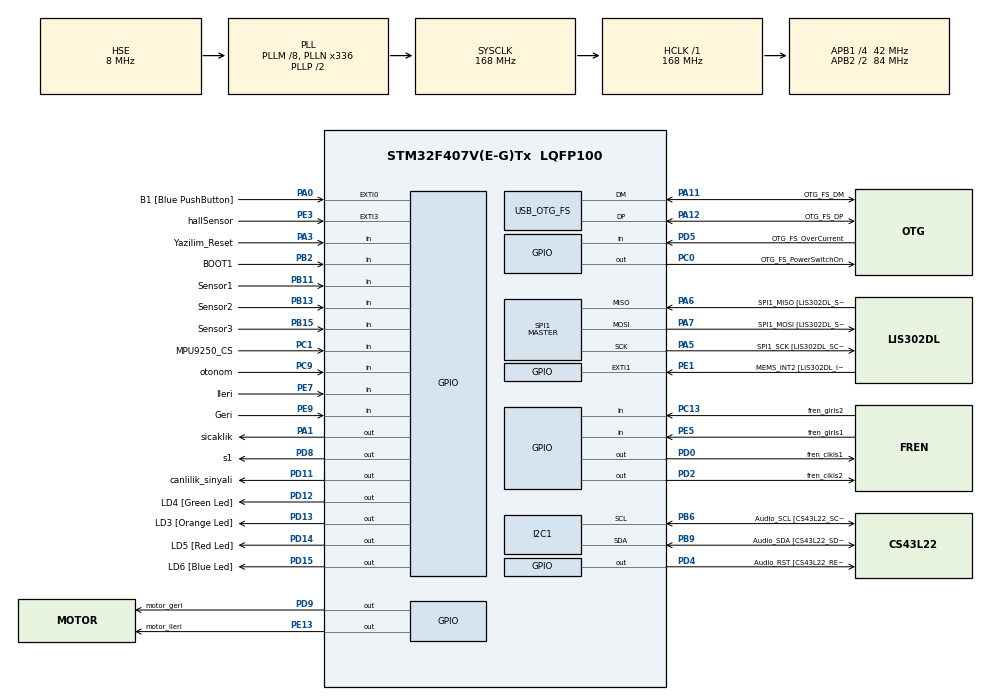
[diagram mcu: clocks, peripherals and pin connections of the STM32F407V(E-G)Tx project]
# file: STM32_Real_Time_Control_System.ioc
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FREERTOS.Tasks01=ControlTask,48,512,StartControlTask,Default,NULL,Dynamic,NULL,NULL;NavigationTask,8,1024,StartNavigationTask,Default,NULL,Dynamic,NULL,NULL;IMUTask,8,512,StartIMUTask,Default,NULL,Dynamic,NULL,NULL;SensorTask,8,512,StartSensorTask,Default,NULL,Dynamic,NULL,NULL;TelemetryTask,8,1024,StartTelemetryTask,Default,NULL,Dynamic,NULL,NULL;ReflectorTask,40,512,StartReflectorTask,Default,NULL,Dynamic,NULL,NULL
FREERTOS.configUSE_NEWLIB_REENTRANT=1
Mcu.Family=STM32F4
Mcu.Name=STM32F407V(E-G)Tx
Mcu.Package=LQFP100
NVIC.OTG_FS_IRQn=true\:5\:0\:false\:false\:true\:true\:true\:true\:true
NVIC.PriorityGroup=NVIC_PRIORITYGROUP_4
NVIC.TIM6_DAC_IRQn=true\:15\:0\:false\:false\:true\:false\:false\:true\:true
NVIC.TimeBase=TIM6_DAC_IRQn
NVIC.TimeBaseIP=TIM6
PA0-WKUP.GPIO_Label=B1 [Blue PushButton]
PA0-WKUP.GPIO_ModeDefaultEXTI=GPIO_MODE_EVT_RISING
PA0-WKUP.GPIO_PuPd=GPIO_NOPULL
PA0-WKUP.Signal=GPXTI0
PA1.GPIO_Label=sicaklik
PA1.GPIO_ModeDefaultOutputPP=GPIO_MODE_OUTPUT_OD
PA1.GPIO_PuPd=GPIO_PULLUP
PA1.GPIO_Speed=GPIO_SPEED_FREQ_HIGH
PA1.Signal=GPIO_Output
PA10.GPIO_Label=OTG_FS_ID
PA10.GPIO_Mode=GPIO_MODE_AF_PP
PA10.GPIO_PuPd=GPIO_NOPULL
PA10.GPIO_Speed=GPIO_SPEED_FREQ_LOW
PA10.Signal=USB_OTG_FS_ID
PA11.GPIO_Label=OTG_FS_DM
PA11.GPIO_Mode=GPIO_MODE_AF_PP
PA11.GPIO_PuPd=GPIO_NOPULL
PA11.GPIO_Speed=GPIO_SPEED_FREQ_LOW
PA11.Mode=Device_Only
PA11.Signal=USB_OTG_FS_DM
PA12.GPIO_Label=OTG_FS_DP
PA12.GPIO_Mode=GPIO_MODE_AF_PP
PA12.GPIO_PuPd=GPIO_NOPULL
PA12.GPIO_Speed=GPIO_SPEED_FREQ_LOW
PA12.Mode=Device_Only
PA12.Signal=USB_OTG_FS_DP
PA13.GPIO_Label=SWDIO
PA13.Mode=Serial_Wire
PA13.Signal=SYS_JTMS-SWDIO
PA14.GPIO_Label=SWCLK
PA14.Mode=Serial_Wire
PA14.Signal=SYS_JTCK-SWCLK
PA3.GPIO_Label=Yazilim_Reset
PA3.GPIO_PuPd=GPIO_PULLDOWN
PA3.Signal=GPIO_Input
PA4.GPIO_Label=I2S3_WS [CS43L22_LRCK]
PA4.GPIO_Mode=GPIO_MODE_AF_PP
PA4.GPIO_PuPd=GPIO_NOPULL
PA4.GPIO_Speed=GPIO_SPEED_FREQ_LOW
PA4.Signal=I2S3_WS
PA5.GPIO_Label=SPI1_SCK [LIS302DL_SCL/SPC]
PA5.GPIO_Mode=GPIO_MODE_AF_PP
PA5.GPIO_PuPd=GPIO_NOPULL
PA5.GPIO_Speed=GPIO_SPEED_FREQ_LOW
PA5.Mode=Full_Duplex_Master
PA5.Signal=SPI1_SCK
PA6.GPIO_Label=SPI1_MISO [LIS302DL_SDO]
PA6.GPIO_Mode=GPIO_MODE_AF_PP
PA6.GPIO_PuPd=GPIO_NOPULL
PA6.GPIO_Speed=GPIO_SPEED_FREQ_LOW
PA6.Mode=Full_Duplex_Master
PA6.Signal=SPI1_MISO
PA7.GPIO_Label=SPI1_MOSI [LIS302DL_SDA/SDI/SDO]
PA7.GPIO_Mode=GPIO_MODE_AF_PP
PA7.GPIO_PuPd=GPIO_NOPULL
PA7.GPIO_Speed=GPIO_SPEED_FREQ_LOW
PA7.Mode=Full_Duplex_Master
PA7.Signal=SPI1_MOSI
PA9.GPIO_Label=VBUS_FS
PA9.GPIO_Mode=GPIO_MODE_INPUT
PA9.GPIO_PuPd=GPIO_NOPULL
PA9.Signal=USB_OTG_FS_VBUS
PB10.GPIO_Label=CLK_IN [MP45DT02_CLK]
PB10.GPIO_Mode=GPIO_MODE_AF_PP
PB10.GPIO_PuPd=GPIO_NOPULL
PB10.GPIO_Speed=GPIO_SPEED_FREQ_LOW
PB10.Signal=I2S2_CK
PB11.GPIO_Label=Sensor1
PB11.GPIO_PuPd=GPIO_NOPULL
PB11.Signal=GPIO_Input
PB13.GPIO_Label=Sensor2
PB13.GPIO_PuPd=GPIO_NOPULL
PB13.Signal=GPIO_Input
PB15.GPIO_Label=Sensor3
PB15.GPIO_PuPd=GPIO_NOPULL
PB15.Signal=GPIO_Input
PB2.GPIO_Label=BOOT1
PB2.GPIO_Mode=GPIO_MODE_INPUT
PB2.GPIO_PuPd=GPIO_NOPULL
PB2.Signal=GPIO_Input
PB3.GPIO_Label=SWO
PB3.Signal=SYS_JTDO-SWO
PB6.GPIO_Label=Audio_SCL [CS43L22_SCL]
PB6.GPIO_Mode=GPIO_MODE_AF_OD
PB6.GPIO_Pu=GPIO_PULLUP
PB6.GPIO_PuPd=GPIO_NOPULL
PB6.GPIO_Speed=GPIO_SPEED_FREQ_HIGH
PB6.Mode=I2C
PB6.Signal=I2C1_SCL
PB9.GPIO_Label=Audio_SDA [CS43L22_SDA]
PB9.GPIO_Mode=GPIO_MODE_AF_OD
PB9.GPIO_Pu=GPIO_PULLUP
PB9.GPIO_PuPd=GPIO_NOPULL
PB9.GPIO_Speed=GPIO_SPEED_FREQ_HIGH
PB9.Mode=I2C
PB9.Signal=I2C1_SDA
PC0.GPIO_Label=OTG_FS_PowerSwitchOn
PC0.GPIO_PuPd=GPIO_NOPULL
PC0.GPIO_Speed=GPIO_SPEED_FREQ_LOW
PC0.PinState=GPIO_PIN_SET
PC0.Signal=GPIO_Output
PC1.GPIO_Label=MPU9250_CS
PC1.Signal=GPIO_Input
PC10.GPIO_Label=I2S3_SCK [CS43L22_SCLK]
PC10.GPIO_Mode=GPIO_MODE_AF_PP
PC10.GPIO_PuPd=GPIO_NOPULL
PC10.GPIO_Speed=GPIO_SPEED_FREQ_LOW
PC10.Signal=I2S3_CK
PC13-ANTI_TAMP.GPIO_Label=fren_giris2
PC13-ANTI_TAMP.GPIO_PuPd=GPIO_PULLDOWN
PC13-ANTI_TAMP.Signal=GPIO_Input
PC14-OSC32_IN.GPIO_Label=PC14-OSC32_IN
PC14-OSC32_IN.Mode=LSE-External-Oscillator
PC14-OSC32_IN.Signal=RCC_OSC32_IN
PC15-OSC32_OUT.GPIO_Label=PC15-OSC32_OUT
PC15-OSC32_OUT.Mode=LSE-External-Oscillator
PC15-OSC32_OUT.Signal=RCC_OSC32_OUT
PC3.GPIO_Label=PDM_OUT [MP45DT02_DOUT]
PC3.GPIO_Mode=GPIO_MODE_AF_PP
PC3.GPIO_PuPd=GPIO_NOPULL
PC3.GPIO_Speed=GPIO_SPEED_FREQ_LOW
PC3.Signal=I2S2_SD
PC7.GPIO_Label=I2S3_MCK [CS43L22_MCLK]
PC7.GPIO_Mode=GPIO_MODE_AF_PP
PC7.GPIO_PuPd=GPIO_NOPULL
PC7.GPIO_Speed=GPIO_SPEED_FREQ_LOW
PC7.Signal=I2S3_MCK
PC9.GPIO_Label=otonom
PC9.GPIO_PuPd=GPIO_PULLDOWN
PC9.Signal=GPIO_Input
PD0.GPIO_Label=fren_cikis1
PD0.PinState=GPIO_PIN_SET
PD0.Signal=GPIO_Output
PD11.GPIO_Label=canlilik_sinyali
PD11.Signal=GPIO_Output
PD12.GPIO_Label=LD4 [Green Led]
PD12.GPIO_PuPd=GPIO_NOPULL
PD12.GPIO_Speed=GPIO_SPEED_FREQ_LOW
PD12.Signal=GPIO_Output
PD13.GPIO_Label=LD3 [Orange Led]
PD13.GPIO_PuPd=GPIO_NOPULL
PD13.GPIO_Speed=GPIO_SPEED_FREQ_LOW
PD13.Signal=GPIO_Output
PD14.GPIO_Label=LD5 [Red Led]
PD14.GPIO_PuPd=GPIO_NOPULL
PD14.GPIO_Speed=GPIO_SPEED_FREQ_LOW
PD14.Signal=GPIO_Output
PD15.GPIO_Label=LD6 [Blue Led]
PD15.GPIO_PuPd=GPIO_NOPULL
PD15.GPIO_Speed=GPIO_SPEED_FREQ_LOW
PD15.Signal=GPIO_Output
PD2.GPIO_Label=fren_cikis2
PD2.GPIO_ModeDefaultOutputPP=GPIO_MODE_OUTPUT_OD
PD2.GPIO_PuPd=GPIO_PULLUP
PD2.PinState=GPIO_PIN_SET
PD2.Signal=GPIO_Output
PD4.GPIO_Label=Audio_RST [CS43L22_RESET]
PD4.GPIO_PuPd=GPIO_NOPULL
PD4.GPIO_Speed=GPIO_SPEED_FREQ_LOW
PD4.Signal=GPIO_Output
PD5.GPIO_Label=OTG_FS_OverCurrent
PD5.GPIO_Mode=GPIO_MODE_INPUT
PD5.GPIO_PuPd=GPIO_NOPULL
PD5.Signal=GPIO_Input
PD8.GPIO_Label=s1
PD8.Signal=GPIO_Output
PD9.GPIO_Label=motor_geri
PD9.PinState=GPIO_PIN_SET
PD9.Signal=GPIO_Output
PE1.GPIO_Label=MEMS_INT2 [LIS302DL_INT2]
PE1.GPIO_ModeDefaultEXTI=GPIO_MODE_EVT_RISING
PE1.GPIO_PuPd=GPIO_NOPULL
PE1.Signal=GPXTI1
PE13.GPIO_Label=motor_ileri
PE13.PinState=GPIO_PIN_SET
PE13.Signal=GPIO_Output
PE3.GPIO_Label=hallSensor
PE3.GPIO_ModeDefaultEXTI=GPIO_MODE_IT_FALLING
PE3.GPIO_PuPd=GPIO_PULLDOWN
PE3.Signal=GPXTI3
PE5.GPIO_Label=fren_giris1
PE5.GPIO_PuPd=GPIO_PULLDOWN
PE5.Signal=GPIO_Input
PE7.GPIO_Label=Ileri
PE7.GPIO_PuPd=GPIO_PULLDOWN
PE7.Signal=GPIO_Input
PE9.GPIO_Label=Geri
PE9.GPIO_PuPd=GPIO_PULLDOWN
PE9.Signal=GPIO_Input
PH0-OSC_IN.GPIO_Label=PH0-OSC_IN
PH0-OSC_IN.Mode=HSE-External-Oscillator
PH0-OSC_IN.Signal=RCC_OSC_IN
PH1-OSC_OUT.GPIO_Label=PH1-OSC_OUT
PH1-OSC_OUT.Mode=HSE-External-Oscillator
PH1-OSC_OUT.Signal=RCC_OSC_OUT
ProjectManager.HeapSize=0x200
ProjectManager.StackSize=0x400
ProjectManager.TargetToolchain=STM32CubeIDE
RCC.48MHZClocksFreq_Value=48000000
RCC.AHBFreq_Value=168000000
RCC.APB1CLKDivider=RCC_HCLK_DIV4
RCC.APB1Freq_Value=42000000
RCC.APB1TimFreq_Value=84000000
RCC.APB2CLKDivider=RCC_HCLK_DIV2
RCC.APB2Freq_Value=84000000
RCC.APB2TimFreq_Value=168000000
RCC.CortexFreq_Value=168000000
RCC.HCLKFreq_Value=168000000
RCC.HSE_VALUE=8000000
RCC.HSI_VALUE=16000000
RCC.PLLM=8
RCC.PLLN=336
RCC.PLLQ=7
RCC.SYSCLKFreq_VALUE=168000000
RCC.SYSCLKSource=RCC_SYSCLKSOURCE_PLLCLK
RCC.VCOOutputFreq_Value=336000000
SPI1.BaudRatePrescaler-Full_Duplex_Master=SPI_BAUDRATEPRESCALER_2
SPI1.CalculateBaudRate-Full_Duplex_Master=42.0 MBits/s
SPI1.Direction=SPI_DIRECTION_2LINES
SPI1.Mode=SPI_MODE_MASTER
SPI1.Mode-Full_Duplex_Master=SPI_MODE_MASTER
SPI1.VirtualType=VM_MASTER
TIM2.Prescaler=83
USB_DEVICE.CLASS_NAME_FS=CDC
USB_DEVICE.VirtualMode-CDC_FS=Cdc
USB_DEVICE.VirtualModeFS=Cdc_FS
USB_OTG_FS.VirtualMode=Device_Only
VP_FREERTOS_VS_CMSIS_V2.Mode=CMSIS_V2
VP_SYS_VS_tim6.Mode=TIM6
VP_TIM2_VS_ClockSourceINT.Mode=Internal
VP_USB_DEVICE_VS_USB_DEVICE_CDC_FS.Mode=CDC_FS
board=STM32F407G-DISC1

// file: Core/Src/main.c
/* USER CODE BEGIN Header */
/**
  ******************************************************************************
  * @file           : main.c
  * @brief          : Main program body
  ******************************************************************************
  * @attention
  *
  * Copyright (c) 2026 STMicroelectronics.
  * All rights reserved.
  *
  * This software is licensed under terms that can be found in the LICENSE file
  * in the root directory of this software component.
  * If no LICENSE file comes with this software, it is provided AS-IS.
  *
  ******************************************************************************
  */
/* USER CODE END Header */
#include "main.h"
#include "cmsis_os.h"
#include "usb_device.h"

I2C_HandleTypeDef hi2c1;

SPI_HandleTypeDef hspi1;

TIM_HandleTypeDef htim2;

/* Definitions for ControlTask */
osThreadId_t ControlTaskHandle;
const osThreadAttr_t ControlTask_attributes = {
  .name = "ControlTask",
  .stack_size = 512 * 4,
  .priority = (osPriority_t) osPriorityRealtime,
};
/* Definitions for NavigationTask */
osThreadId_t NavigationTaskHandle;
const osThreadAttr_t NavigationTask_attributes = {
  .name = "NavigationTask",
  .stack_size = 1024 * 4,
  .priority = (osPriority_t) osPriorityLow,
};
/* Definitions for IMUTask */
osThreadId_t IMUTaskHandle;
const osThreadAttr_t IMUTask_attributes = {
  .name = "IMUTask",
  .stack_size = 512 * 4,
  .priority = (osPriority_t) osPriorityLow,
};
/* Definitions for SensorTask */
osThreadId_t SensorTaskHandle;
const osThreadAttr_t SensorTask_attributes = {
  .name = "SensorTask",
  .stack_size = 512 * 4,
  .priority = (osPriority_t) osPriorityLow,
};
/* Definitions for TelemetryTask */
osThreadId_t TelemetryTaskHandle;
const osThreadAttr_t TelemetryTask_attributes = {
  .name = "TelemetryTask",
  .stack_size = 1024 * 4,
  .priority = (osPriority_t) osPriorityLow,
};

void SystemClock_Config(void);
static void MX_GPIO_Init(void);
static void MX_I2C1_Init(void);
static void MX_SPI1_Init(void);
static void MX_TIM2_Init(void);
void StartControlTask(void *argument);
void StartNavigationTask(void *argument);
void StartIMUTask(void *argument);
void StartSensorTask(void *argument);
void StartTelemetryTask(void *argument);

/* USER CODE BEGIN 0 */
void I2C_Hatti_Kurtar(void)
{
    GPIO_InitTypeDef GPIO_InitStruct = {0};
    __HAL_RCC_GPIOB_CLK_ENABLE();

    // SCL (PB6) ve SDA (PB9) pinlerini standart çıkış olarak ayarla
    GPIO_InitStruct.Pin = GPIO_PIN_6 | GPIO_PIN_9;
    GPIO_InitStruct.Mode = GPIO_MODE_OUTPUT_OD; // Open Drain
    GPIO_InitStruct.Pull = GPIO_PULLUP;
    GPIO_InitStruct.Speed = GPIO_SPEED_FREQ_HIGH;
    HAL_GPIO_Init(GPIOB, &GPIO_InitStruct);

    // SDA'yı serbest bırak ve SCL'ye 9 kez manuel saat palsi gönder (Sensörü hattan düşür)
    HAL_GPIO_WritePin(GPIOB, GPIO_PIN_9, GPIO_PIN_SET);

    for(int i = 0; i < 9; i++)
    {
        HAL_GPIO_WritePin(GPIOB, GPIO_PIN_6, GPIO_PIN_RESET); // SCL Low
        HAL_Delay(1);
        HAL_GPIO_WritePin(GPIOB, GPIO_PIN_6, GPIO_PIN_SET);   // SCL High
        HAL_Delay(1);
    }

    // STOP durumu oluştur
    HAL_GPIO_WritePin(GPIOB, GPIO_PIN_6, GPIO_PIN_RESET);
    HAL_Delay(1);
    HAL_GPIO_WritePin(GPIOB, GPIO_PIN_9, GPIO_PIN_RESET);
    HAL_Delay(1);
    HAL_GPIO_WritePin(GPIOB, GPIO_PIN_6, GPIO_PIN_SET);
    HAL_Delay(1);
    HAL_GPIO_WritePin(GPIOB, GPIO_PIN_9, GPIO_PIN_SET);
    HAL_Delay(1);
}
/* USER CODE END 0 */

int main(void)
{

  /* MCU Configuration--------------------------------------------------------*/

  /* Reset of all peripherals, Initializes the Flash interface and the Systick. */
  HAL_Init();

  /* Configure the system clock */
  SystemClock_Config();

  /* Initialize all configured peripherals */
  MX_GPIO_Init();

  /*
   * Bataryadan ilk enerji verildiginde BNO055'in dahili regilatorunun,
   * islemcisinin ve I2C cikislarinin tamamen hazir olmasini bekle.
   * USB ile beslemede olusan dogal gecikme bataryada bulunmadigi icin
   * bu bekleme soguk acilis sorununu engeller.
   */
  HAL_Delay(1500);

  /* BNO055 acilista I2C hattini kilitlediyse 9 SCL palsi ve STOP ile kurtar. */
  I2C_Hatti_Kurtar();

  /* GPIO modundan I2C alternatif fonksiyonuna gecmeden once hatti serbest birak. */
  HAL_Delay(10);

  MX_I2C1_Init();
  MX_SPI1_Init();
  MX_TIM2_Init();
  MX_USB_DEVICE_Init();
  /* USER CODE BEGIN 2 */
  HAL_TIM_Base_Start(&htim2);
  /* USER CODE END 2 */

  /* Init scheduler */
  osKernelInitialize();

  /* Create the thread(s) */
  /* creation of ControlTask */
  ControlTaskHandle = osThreadNew(StartControlTask, NULL, &ControlTask_attributes);

  /* creation of NavigationTask */
  NavigationTaskHandle = osThreadNew(StartNavigationTask, NULL, &NavigationTask_attributes);

  /* creation of IMUTask */
  IMUTaskHandle = osThreadNew(StartIMUTask, NULL, &IMUTask_attributes);

  /* creation of SensorTask */
  SensorTaskHandle = osThreadNew(StartSensorTask, NULL, &SensorTask_attributes);

  /* creation of TelemetryTask */
  TelemetryTaskHandle = osThreadNew(StartTelemetryTask, NULL, &TelemetryTask_attributes);

  /* Start scheduler */
  osKernelStart();

  /* We should never get here as control is now taken by the scheduler */

  /* Infinite loop */
  while (1)
  {

  }
}

void SystemClock_Config(void)
{
  RCC_OscInitTypeDef RCC_OscInitStruct = {0};
  RCC_ClkInitTypeDef RCC_ClkInitStruct = {0};

  /** Configure the main internal regulator output voltage
  */
  __HAL_RCC_PWR_CLK_ENABLE();
  __HAL_PWR_VOLTAGESCALING_CONFIG(PWR_REGULATOR_VOLTAGE_SCALE1);

  /** Initializes the RCC Oscillators according to the specified parameters in the RCC_OscInitTypeDef structure.
  */
  RCC_OscInitStruct.OscillatorType = RCC_OSCILLATORTYPE_HSE;
  RCC_OscInitStruct.HSEState = RCC_HSE_ON;
  RCC_OscInitStruct.PLL.PLLState = RCC_PLL_ON;
  RCC_OscInitStruct.PLL.PLLSource = RCC_PLLSOURCE_HSE;
  RCC_OscInitStruct.PLL.PLLM = 8;
  RCC_OscInitStruct.PLL.PLLN = 336;
  RCC_OscInitStruct.PLL.PLLP = RCC_PLLP_DIV2;
  RCC_OscInitStruct.PLL.PLLQ = 7;
  if (HAL_RCC_OscConfig(&RCC_OscInitStruct) != HAL_OK)
  {
    Error_Handler();
  }

  /** Initializes the CPU, AHB and APB buses clocks
  */
  RCC_ClkInitStruct.ClockType = RCC_CLOCKTYPE_HCLK|RCC_CLOCKTYPE_SYSCLK
                              |RCC_CLOCKTYPE_PCLK1|RCC_CLOCKTYPE_PCLK2;
  RCC_ClkInitStruct.SYSCLKSource = RCC_SYSCLKSOURCE_PLLCLK;
  RCC_ClkInitStruct.AHBCLKDivider = RCC_SYSCLK_DIV1;
  RCC_ClkInitStruct.APB1CLKDivider = RCC_HCLK_DIV4;
  RCC_ClkInitStruct.APB2CLKDivider = RCC_HCLK_DIV2;

  if (HAL_RCC_ClockConfig(&RCC_ClkInitStruct, FLASH_LATENCY_5) != HAL_OK)
  {
    Error_Handler();
  }
}

static void MX_I2C1_Init(void)
{

  hi2c1.Instance = I2C1;
  hi2c1.Init.ClockSpeed = 100000;
  hi2c1.Init.DutyCycle = I2C_DUTYCYCLE_2;
  hi2c1.Init.OwnAddress1 = 0;
  hi2c1.Init.AddressingMode = I2C_ADDRESSINGMODE_7BIT;
  hi2c1.Init.DualAddressMode = I2C_DUALADDRESS_DISABLE;
  hi2c1.Init.OwnAddress2 = 0;
  hi2c1.Init.GeneralCallMode = I2C_GENERALCALL_DISABLE;
  hi2c1.Init.NoStretchMode = I2C_NOSTRETCH_DISABLE;
  if (HAL_I2C_Init(&hi2c1) != HAL_OK)
  {
    Error_Handler();
  }

}

static void MX_SPI1_Init(void)
{

  /* SPI1 parameter configuration*/
  hspi1.Instance = SPI1;
  hspi1.Init.Mode = SPI_MODE_MASTER;
  hspi1.Init.Direction = SPI_DIRECTION_2LINES;
  hspi1.Init.DataSize = SPI_DATASIZE_8BIT;
  hspi1.Init.CLKPolarity = SPI_POLARITY_LOW;
  hspi1.Init.CLKPhase = SPI_PHASE_1EDGE;
  hspi1.Init.NSS = SPI_NSS_SOFT;
  hspi1.Init.BaudRatePrescaler = SPI_BAUDRATEPRESCALER_2;
  hspi1.Init.FirstBit = SPI_FIRSTBIT_MSB;
  hspi1.Init.TIMode = SPI_TIMODE_DISABLE;
  hspi1.Init.CRCCalculation = SPI_CRCCALCULATION_DISABLE;
  hspi1.Init.CRCPolynomial = 10;
  if (HAL_SPI_Init(&hspi1) != HAL_OK)
  {
    Error_Handler();
  }
  /* USER CODE BEGIN SPI1_Init 2 */
  HAL_NVIC_EnableIRQ(EXTI3_IRQn);
  /* USER CODE END SPI1_Init 2 */

}

static void MX_TIM2_Init(void)
{

  TIM_ClockConfigTypeDef sClockSourceConfig = {0};
  TIM_MasterConfigTypeDef sMasterConfig = {0};

  htim2.Instance = TIM2;
  htim2.Init.Prescaler = 83;
  htim2.Init.CounterMode = TIM_COUNTERMODE_UP;
  htim2.Init.Period = 4294967295;
  htim2.Init.ClockDivision = TIM_CLOCKDIVISION_DIV1;
  htim2.Init.AutoReloadPreload = TIM_AUTORELOAD_PRELOAD_DISABLE;
  if (HAL_TIM_Base_Init(&htim2) != HAL_OK)
  {
    Error_Handler();
  }
  sClockSourceConfig.ClockSource = TIM_CLOCKSOURCE_INTERNAL;
  if (HAL_TIM_ConfigClockSource(&htim2, &sClockSourceConfig) != HAL_OK)
  {
    Error_Handler();
  }
  sMasterConfig.MasterOutputTrigger = TIM_TRGO_RESET;
  sMasterConfig.MasterSlaveMode = TIM_MASTERSLAVEMODE_DISABLE;
  if (HAL_TIMEx_MasterConfigSynchronization(&htim2, &sMasterConfig) != HAL_OK)
  {
    Error_Handler();
  }

}

static void MX_GPIO_Init(void)
{
  GPIO_InitTypeDef GPIO_InitStruct = {0};

  /* GPIO Ports Clock Enable */
  __HAL_RCC_GPIOE_CLK_ENABLE();
  __HAL_RCC_GPIOC_CLK_ENABLE();
  __HAL_RCC_GPIOH_CLK_ENABLE();
  __HAL_RCC_GPIOA_CLK_ENABLE();
  __HAL_RCC_GPIOB_CLK_ENABLE();
  __HAL_RCC_GPIOD_CLK_ENABLE();

  /*Configure GPIO pin Output Level */
  HAL_GPIO_WritePin(OTG_FS_PowerSwitchOn_GPIO_Port, OTG_FS_PowerSwitchOn_Pin, GPIO_PIN_SET);

  /*Configure GPIO pin Output Level */
  HAL_GPIO_WritePin(sicaklik_GPIO_Port, sicaklik_Pin, GPIO_PIN_RESET);

  /*Configure GPIO pin Output Level */
  HAL_GPIO_WritePin(GPIOE, motor_ileri_Pin|fren_cikis1_Pin, GPIO_PIN_SET);

  /*Configure GPIO pin Output Level */
  HAL_GPIO_WritePin(GPIOD, s1_Pin|canlilik_sinyali_Pin|LD4_Pin|LD3_Pin
                          |LD5_Pin|LD6_Pin|Audio_RST_Pin, GPIO_PIN_RESET);

  /*Configure GPIO pin Output Level */
  HAL_GPIO_WritePin(GPIOD, motor_geri_Pin|fren_cikis2_Pin, GPIO_PIN_SET);

  /* I2C modunda GY-91 MPU NCS pini HIGH tutulur. */
  HAL_GPIO_WritePin(MPU9250_CS_GPIO_Port, MPU9250_CS_Pin, GPIO_PIN_SET);

  /*Configure GPIO pin : hallSensor_Pin */
  GPIO_InitStruct.Pin = hallSensor_Pin;
  GPIO_InitStruct.Mode = GPIO_MODE_IT_RISING_FALLING;
  GPIO_InitStruct.Pull = GPIO_NOPULL;
  HAL_GPIO_Init(hallSensor_GPIO_Port, &GPIO_InitStruct);

  /*Configure GPIO pins : fren_giris1_Pin Ileri_Pin Geri_Pin */
  GPIO_InitStruct.Pin = fren_giris1_Pin|Ileri_Pin|Geri_Pin;
  GPIO_InitStruct.Mode = GPIO_MODE_INPUT;
  GPIO_InitStruct.Pull = GPIO_PULLDOWN;
  HAL_GPIO_Init(GPIOE, &GPIO_InitStruct);

  /*Configure GPIO pins : fren_giris2_Pin otonom_Pin */
  GPIO_InitStruct.Pin = fren_giris2_Pin|otonom_Pin;
  GPIO_InitStruct.Mode = GPIO_MODE_INPUT;
  GPIO_InitStruct.Pull = GPIO_PULLDOWN;
  HAL_GPIO_Init(GPIOC, &GPIO_InitStruct);

  /*Configure GPIO pin : OTG_FS_PowerSwitchOn_Pin */
  GPIO_InitStruct.Pin = OTG_FS_PowerSwitchOn_Pin;
  GPIO_InitStruct.Mode = GPIO_MODE_OUTPUT_PP;
  GPIO_InitStruct.Pull = GPIO_NOPULL;
  GPIO_InitStruct.Speed = GPIO_SPEED_FREQ_LOW;
  HAL_GPIO_Init(OTG_FS_PowerSwitchOn_GPIO_Port, &GPIO_InitStruct);

  /*Configure GPIO pin : MPU9250_CS_Pin */
  GPIO_InitStruct.Pin = MPU9250_CS_Pin;
  GPIO_InitStruct.Mode = GPIO_MODE_OUTPUT_PP;
  GPIO_InitStruct.Pull = GPIO_NOPULL;
  GPIO_InitStruct.Speed = GPIO_SPEED_FREQ_LOW;
  HAL_GPIO_Init(MPU9250_CS_GPIO_Port, &GPIO_InitStruct);

  HAL_GPIO_WritePin(MPU9250_CS_GPIO_Port, MPU9250_CS_Pin, GPIO_PIN_SET);

  /*Configure GPIO pin : PDM_OUT_Pin */
  GPIO_InitStruct.Pin = PDM_OUT_Pin;
  GPIO_InitStruct.Mode = GPIO_MODE_AF_PP;
  GPIO_InitStruct.Pull = GPIO_NOPULL;
  GPIO_InitStruct.Speed = GPIO_SPEED_FREQ_LOW;
  GPIO_InitStruct.Alternate = GPIO_AF5_SPI2;
  HAL_GPIO_Init(PDM_OUT_GPIO_Port, &GPIO_InitStruct);

  /*Configure GPIO pin : B1_Pin */
  GPIO_InitStruct.Pin = B1_Pin;
  GPIO_InitStruct.Mode = GPIO_MODE_EVT_RISING;
  GPIO_InitStruct.Pull = GPIO_NOPULL;
  HAL_GPIO_Init(B1_GPIO_Port, &GPIO_InitStruct);

  /*Configure GPIO pin : sicaklik_Pin */
  GPIO_InitStruct.Pin = sicaklik_Pin;
  GPIO_InitStruct.Mode = GPIO_MODE_OUTPUT_OD;
  GPIO_InitStruct.Pull = GPIO_PULLUP;
  GPIO_InitStruct.Speed = GPIO_SPEED_FREQ_HIGH;
  HAL_GPIO_Init(sicaklik_GPIO_Port, &GPIO_InitStruct);

  /*Configure GPIO pin : Yazilim_Reset_Pin */
  GPIO_InitStruct.Pin = Yazilim_Reset_Pin;
  GPIO_InitStruct.Mode = GPIO_MODE_INPUT;
  GPIO_InitStruct.Pull = GPIO_PULLDOWN;
  HAL_GPIO_Init(Yazilim_Reset_GPIO_Port, &GPIO_InitStruct);

  /*Configure GPIO pin : I2S3_WS_Pin */
  GPIO_InitStruct.Pin = I2S3_WS_Pin;
  GPIO_InitStruct.Mode = GPIO_MODE_AF_PP;
  GPIO_InitStruct.Pull = GPIO_NOPULL;
  GPIO_InitStruct.Speed = GPIO_SPEED_FREQ_LOW;
  GPIO_InitStruct.Alternate = GPIO_AF6_SPI3;
  HAL_GPIO_Init(I2S3_WS_GPIO_Port, &GPIO_InitStruct);

  /*Configure GPIO pins : BOOT1_Pin Sensor1_Pin Sensor2_Pin Sensor3_Pin */
  GPIO_InitStruct.Pin = BOOT1_Pin|Sensor1_Pin|Sensor2_Pin|Sensor3_Pin;
  GPIO_InitStruct.Mode = GPIO_MODE_INPUT;
  GPIO_InitStruct.Pull = GPIO_NOPULL;
  HAL_GPIO_Init(GPIOB, &GPIO_InitStruct);

  /*Configure GPIO pin : motor_ileri_Pin */
  GPIO_InitStruct.Pin = motor_ileri_Pin;
  GPIO_InitStruct.Mode = GPIO_MODE_OUTPUT_PP;
  GPIO_InitStruct.Pull = GPIO_NOPULL;
  GPIO_InitStruct.Speed = GPIO_SPEED_FREQ_LOW;
  HAL_GPIO_Init(motor_ileri_GPIO_Port, &GPIO_InitStruct);

  /*Configure GPIO pin : fren_cikis1_Pin */
  GPIO_InitStruct.Pin = fren_cikis1_Pin;
  GPIO_InitStruct.Mode = GPIO_MODE_OUTPUT_OD;
  GPIO_InitStruct.Pull = GPIO_PULLUP;
  GPIO_InitStruct.Speed = GPIO_SPEED_FREQ_LOW;
  HAL_GPIO_Init(fren_cikis1_GPIO_Port, &GPIO_InitStruct);

  /*Configure GPIO pin : CLK_IN_Pin */
  GPIO_InitStruct.Pin = CLK_IN_Pin;
  GPIO_InitStruct.Mode = GPIO_MODE_AF_PP;
  GPIO_InitStruct.Pull = GPIO_NOPULL;
  GPIO_InitStruct.Speed = GPIO_SPEED_FREQ_LOW;
  GPIO_InitStruct.Alternate = GPIO_AF5_SPI2;
  HAL_GPIO_Init(CLK_IN_GPIO_Port, &GPIO_InitStruct);

  /*Configure GPIO pins : s1_Pin motor_geri_Pin canlilik_sinyali_Pin LD4_Pin
                           LD3_Pin LD5_Pin LD6_Pin Audio_RST_Pin */
  GPIO_InitStruct.Pin = s1_Pin|motor_geri_Pin|canlilik_sinyali_Pin|LD4_Pin
                          |LD3_Pin|LD5_Pin|LD6_Pin|Audio_RST_Pin;
  GPIO_InitStruct.Mode = GPIO_MODE_OUTPUT_PP;
  GPIO_InitStruct.Pull = GPIO_NOPULL;
  GPIO_InitStruct.Speed = GPIO_SPEED_FREQ_LOW;
  HAL_GPIO_Init(GPIOD, &GPIO_InitStruct);

  /*Configure GPIO pins : I2S3_MCK_Pin I2S3_SCK_Pin */
  GPIO_InitStruct.Pin = I2S3_MCK_Pin|I2S3_SCK_Pin;
  GPIO_InitStruct.Mode = GPIO_MODE_AF_PP;
  GPIO_InitStruct.Pull = GPIO_NOPULL;
  GPIO_InitStruct.Speed = GPIO_SPEED_FREQ_LOW;
  GPIO_InitStruct.Alternate = GPIO_AF6_SPI3;
  HAL_GPIO_Init(GPIOC, &GPIO_InitStruct);

  /*Configure GPIO pin : fren_cikis2_Pin */
  GPIO_InitStruct.Pin = fren_cikis2_Pin;
  GPIO_InitStruct.Mode = GPIO_MODE_OUTPUT_OD;
  GPIO_InitStruct.Pull = GPIO_PULLUP;
  GPIO_InitStruct.Speed = GPIO_SPEED_FREQ_LOW;
  HAL_GPIO_Init(fren_cikis2_GPIO_Port, &GPIO_InitStruct);

  /*Configure GPIO pin : OTG_FS_OverCurrent_Pin */
  GPIO_InitStruct.Pin = OTG_FS_OverCurrent_Pin;
  GPIO_InitStruct.Mode = GPIO_MODE_INPUT;
  GPIO_InitStruct.Pull = GPIO_NOPULL;
  HAL_GPIO_Init(OTG_FS_OverCurrent_GPIO_Port, &GPIO_InitStruct);

  /*Configure GPIO pin : MEMS_INT2_Pin */
  GPIO_InitStruct.Pin = MEMS_INT2_Pin;
  GPIO_InitStruct.Mode = GPIO_MODE_EVT_RISING;
  GPIO_InitStruct.Pull = GPIO_NOPULL;
  HAL_GPIO_Init(MEMS_INT2_GPIO_Port, &GPIO_InitStruct);

  /* EXTI interrupt init*/
  HAL_NVIC_SetPriority(EXTI3_IRQn, 10, 0);
  HAL_NVIC_EnableIRQ(EXTI3_IRQn);

  /* USER CODE BEGIN MX_GPIO_Init_2 */
  /* Enkoder EXTI3 kesmesini kullanır. Çift kenar filtresinin çalışabilmesi
     için kesme GPIO kurulumundan sonra etkin bırakılır. */
  HAL_NVIC_EnableIRQ(EXTI3_IRQn);
  /* USER CODE END MX_GPIO_Init_2 */
}

void HAL_TIM_PeriodElapsedCallback(TIM_HandleTypeDef *htim)
{
  if (htim->Instance == TIM6)
  {
    HAL_IncTick();
  }
}

void Error_Handler(void)
{
  __disable_irq();
  while (1)
  {
  }
}

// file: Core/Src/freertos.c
/* USER CODE BEGIN Header */
/**
  ******************************************************************************
  * File Name          : freertos.c
  * Description        : Code for freertos applications
  ******************************************************************************
  */
/* USER CODE END Header */

#include "FreeRTOS.h"
#include "task.h"
#include "main.h"
#include "math.h"

/* USER CODE BEGIN Includes */
#include "onewire.h"
#include "usbd_cdc_if.h"
#include "usb_device.h"
#include <stdio.h>
#include <stdbool.h>

extern TIM_HandleTypeDef htim2;
/* USER CODE END Includes */

/* USER CODE BEGIN Variables */

volatile float LX = 0.0f;
volatile float SX = 0.0f;
volatile float AS = 0.0f;
volatile float AX = 0.0f;

volatile uint32_t RC1 = 0;
volatile uint32_t RC2 = 0;
volatile uint32_t RC3 = 0;

volatile int32_t TekerlekTur = 0;

volatile uint8_t yon_ileri = 1;

/*
 * 0 = Omron ana kaynak
 * 1 = Enkoder yedek kaynak
 */
volatile uint8_t yedek_mod = 0;

volatile uint8_t debug_oto_durum = 0;

volatile float MT1 = 0.0f;
volatile float MT2 = 0.0f;
volatile float MT3 = 0.0f;

volatile uint8_t sicaklik1_ok = 0U;
volatile uint8_t sicaklik2_ok = 0U;
volatile uint8_t sicaklik3_ok = 0U;

volatile uint32_t HareketSuresi_ms = 0;
volatile uint8_t timerBasladi = 0;
volatile uint8_t tekerlek_durdu = 1;
volatile uint8_t oto_durum = 0;

/* Hareket komutunda 5 saniye boyunca Omron ve encoder verisi gelmezse 1 olur. */
volatile uint8_t H = 0U;
static volatile uint8_t hareketKomutuAktif = 0U;
static uint8_t hareketVeriKontrolAktif = 0U;
static uint32_t hareketSonVeri_ms = 0U;
static uint32_t hareketOncekiOmronOlay = 0U;
static uint32_t hareketOncekiEncoderPals = 0U;

/* Mekanik ve zaman sabitleri */
#define TEKER_CEVRESI_M               0.172788f
#define ENCODER_PPR                    400U
#define ENCODER_MIN_PERIYOT_US         18U
#define ENCODER_MIN_LOW_US             2U
#define ENCODER_MIN_HIGH_US            2U
#define ENCODER_DUTY_MIN_YUZDE         10U
#define ENCODER_DUTY_MAX_YUZDE         90U
#define ENCODER_MIN_TUR_SURESI_US      6500U
#define DURMA_ZAMAN_ASIMI_MS          2000U
#define OMRON_FILTER_SEVIYESI         2U
#define OMRON_ESLESME_BEKLEME_MS      500U
#define OMRON_HIZ_ZAMAN_ASIMI_MS      10000U
#define HAREKET_VERI_ZAMAN_ASIMI_MS    5000U
#define OTONOM_ILERI_FREN_M           150.0f
#define OTONOM_GERI_FREN_M            10.0f

typedef struct
{
    uint8_t integrator;
    GPIO_PinState kararli_durum;
    uint8_t kilitli;
    uint8_t goruldu;
} OmronFiltre_t;

typedef enum
{
    OTO_BOSTA = 0,
    OTO_ILERI,
    OTO_ILERI_FREN,
    OTO_GERI,
    OTO_GERI_FREN,
    OTO_TAMAMLANDI
} OtonomDurum_t;

static OmronFiltre_t omronFiltre[3];

static volatile uint32_t omronOlayNo = 0;

static volatile uint8_t omronSaglikli = 1;
static volatile uint8_t omronBeklemede = 0;
static volatile uint8_t omronDogrulandi = 0;
static volatile uint32_t omronReddedilen = 0;

static uint32_t omronBeklemeBaslangic_ms = 0;
static uint32_t omronSonDogrulama_ms = 0;

static uint8_t omronReferansVar = 0;
static uint32_t omronSonReflektorNo = 0;

static float omronKonum = 0.0f;
static float omronHiz = 0.0f;
static float omronOrtalamaHiz = 0.0f;
static float omronIvme = 0.0f;
static float omronOncekiHiz = 0.0f;
static float omronToplamYol = 0.0f;

/*
 * Enkoder yedeÃ„Å¸inden Omron'a kontrollÃƒÂ¼ dÃƒÂ¶nÃƒÂ¼Ã…Å¸ deÃ„Å¸iÃ…Å¸kenleri.
 * Her ÃƒÂ¶lÃƒÂ§ÃƒÂ¼mde ileri yÃƒÂ¶nde bir, geri yÃƒÂ¶nde bir kez denenir.
 */
static volatile uint8_t omronGecisDenendiIleri = 0U;
static volatile uint8_t omronGecisDenendiGeri = 0U;
static volatile uint8_t omronGecisHedefAktif = 0U;
static volatile uint32_t omronGecisHedefReflektor = 0U;
static volatile int8_t omronGecisHedefYonu = 0;
static float omronGecisHedefKonum = 0.0f;

/*
 * DeÃ„Å¸iÃ…Å¸ken isimleri eski sisteme uyumluluk amacÃ„Â±yla korunmuÃ…Å¸tur.
 * Bu deÃ„Å¸iÃ…Å¸kenler artÃ„Â±k enkoderin oluÃ…Å¸turduÃ„Å¸u tam tur bilgisini tutar.
 */
static volatile uint32_t hallSonPals_us = 0;
static volatile uint32_t hallPeriyot_us = 0;
static volatile uint32_t hallSonPals_ms = 0;
static volatile uint32_t hallToplamPals = 0;

static volatile uint8_t hallKullanilabilir = 0;
static volatile int8_t hareketYonu = 1;

/* Enkoder ham pals ve VFD parazit filtresi deÃ„Å¸iÃ…Å¸kenleri */
static volatile uint16_t encoderPalsSayaci = 0U;
static volatile uint32_t encoderSonTamTur_us = 0U;
static volatile uint32_t encoderTurBaslangic_us = 0U;
static volatile uint32_t encoderSonYukselen_us = 0U;
static volatile uint32_t encoderDusenKenar_us = 0U;
static volatile uint8_t encoderLowBasladi = 0U;
static volatile uint8_t encoderIlkPalsAday = 0U;
static volatile uint8_t encoderFiltreKilitli = 0U;
static volatile uint32_t encoderKabulEdilenPals = 0U;
static volatile uint32_t encoderReddedilenPals = 0U;
static volatile uint32_t encoderSonGecerliPals_ms = 0U;
static volatile uint32_t encoderSonPalsPeriyot_us = 0U;

/* Fren sonrasi encoder saglik ve durus dogrulama degiskenleri */
volatile uint8_t frenEncoderPalsGoruldu = 0U;
volatile uint8_t frenEncoderPeriyotArtisi = 0U;
volatile uint8_t frenEncoderHizDususu = 0U;
volatile uint8_t frenEncoderSaglam = 0U;
volatile uint8_t frenEncoderDurusDogrulandi = 0U;

static uint8_t frenEncoderIzlemeAktif = 0U;
static uint8_t frenEncoderPeriyotArtisSayisi = 0U;
static uint8_t frenEncoderHizDususSayisi = 0U;
static uint32_t frenEncoderBaslangicPals = 0U;
static uint32_t frenEncoderOncekiPeriyot_us = 0U;
static float frenEncoderOncekiHiz = 0.0f;

static float hallKonum = 0.0f;
static float hallHiz = 0.0f;
static float hallOrtalamaHiz = 0.0f;
static float hallIvme = 0.0f;
static float hallOncekiHiz = 0.0f;

static uint32_t hareketBaslangic_ms = 0;

static const uint8_t sensor1_id[8] =
{
    0x28, 0x6A, 0xEB, 0x77,
    0x00, 0x00, 0x00, 0x96
};

static const uint8_t sensor2_id[8] =
{
    0x28, 0x25, 0x08, 0x79,
    0x00, 0x00, 0x00, 0x46
};

static const uint8_t sensor3_id[8] =
{
    0x28, 0xF5, 0x1B, 0x78,
    0x00, 0x00, 0x00, 0x3F
};

/* USER CODE END Variables */

/* USER CODE BEGIN FunctionPrototypes */

void StartControlTask(void *argument);
void StartNavigationTask(void *argument);
void StartIMUTask(void *argument);
void StartSensorTask(void *argument);
void StartTelemetryTask(void *argument);

void TerminalKomutAl(uint8_t *veri, uint32_t uzunluk);

/* USER CODE END FunctionPrototypes */

/* USER CODE BEGIN Application */

uint32_t microsSTM(void)
{
    return __HAL_TIM_GET_COUNTER(&htim2);
}

/* ========================================================= */
/*                  USB KOMUT GIRISI KAPALI                  */
/* ========================================================= */

void TerminalKomutAl(uint8_t *veri, uint32_t uzunluk)
{
    (void)veri;
    (void)uzunluk;
}

/* ========================================================= */
/*                     MOTOR KONTROLÃƒÅ“                         */
/* ========================================================= */

static void MotorlariDurdur(void)
{
    hareketKomutuAktif = 0U;

    HAL_GPIO_WritePin(
        motor_ileri_GPIO_Port,
        motor_ileri_Pin,
        GPIO_PIN_SET);

    HAL_GPIO_WritePin(
        motor_geri_GPIO_Port,
        motor_geri_Pin,
        GPIO_PIN_SET);

    HAL_GPIO_WritePin(
        s1_GPIO_Port,
        s1_Pin,
        GPIO_PIN_SET);
}

static void FrenleriAyarla(uint8_t fren1, uint8_t fren2)
{
    HAL_GPIO_WritePin(
        fren_cikis1_GPIO_Port,
        fren_cikis1_Pin,
        fren1 ? GPIO_PIN_RESET : GPIO_PIN_SET);

    HAL_GPIO_WritePin(
        fren_cikis2_GPIO_Port,
        fren_cikis2_Pin,
        fren2 ? GPIO_PIN_RESET : GPIO_PIN_SET);
}

static void MotorIleri(void)
{
    hareketKomutuAktif = 1U;

    hareketYonu = 1;
    yon_ileri = 1;

    FrenleriAyarla(0, 0);

    HAL_GPIO_WritePin(
        motor_geri_GPIO_Port,
        motor_geri_Pin,
        GPIO_PIN_SET);

    HAL_GPIO_WritePin(
        s1_GPIO_Port,
        s1_Pin,
        GPIO_PIN_SET);

    HAL_GPIO_WritePin(
        motor_ileri_GPIO_Port,
        motor_ileri_Pin,
        GPIO_PIN_RESET);
}

static void MotorGeri(void)
{
    hareketKomutuAktif = 1U;

    hareketYonu = -1;
    yon_ileri = 0;

    FrenleriAyarla(0, 0);

    HAL_GPIO_WritePin(
        motor_ileri_GPIO_Port,
        motor_ileri_Pin,
        GPIO_PIN_SET);

    HAL_GPIO_WritePin(
        s1_GPIO_Port,
        s1_Pin,
        GPIO_PIN_RESET);

    HAL_GPIO_WritePin(
        motor_geri_GPIO_Port,
        motor_geri_Pin,
        GPIO_PIN_RESET);
}

/* ========================================================= */
/*                    Ãƒâ€“LÃƒâ€¡ÃƒÅ“MÃƒÅ“ BAÃ…ÂLAT                           */
/* ========================================================= */

static void OlcumuBaslat(void)
{
    uint32_t simdi = HAL_GetTick();

    taskENTER_CRITICAL();

    LX = 0.0f;
    SX = 0.0f;
    AS = 0.0f;
    AX = 0.0f;

    RC1 = 0;
    RC2 = 0;
    RC3 = 0;

    TekerlekTur = 0;

    hallSonPals_us = 0U;
    hallPeriyot_us = 0U;
    hallSonPals_ms = simdi;
    hallToplamPals = 0U;
    hallKullanilabilir = 0U;

    /*
     * Yeni ÃƒÂ¶lÃƒÂ§ÃƒÂ¼m baÃ…Å¸ladÃ„Â±Ã„Å¸Ã„Â±nda eski ÃƒÂ¶lÃƒÂ§ÃƒÂ¼mden kalan eksik enkoder
     * palsleri ve eski tam tur zamanÃ„Â± mutlaka sÃ„Â±fÃ„Â±rlanÃ„Â±r.
     */
    encoderPalsSayaci = 0U;
    encoderSonTamTur_us = 0U;
    encoderTurBaslangic_us = 0U;
    encoderSonYukselen_us = 0U;
    encoderDusenKenar_us = 0U;
    encoderLowBasladi = 0U;
    encoderIlkPalsAday = 0U;
    encoderFiltreKilitli = 0U;
    encoderKabulEdilenPals = 0U;
    encoderReddedilenPals = 0U;
    encoderSonGecerliPals_ms = 0U;
    encoderSonPalsPeriyot_us = 0U;

    omronOlayNo = 0U;

    taskEXIT_CRITICAL();

    for (uint8_t i = 0; i < 3; i++)
    {
        omronFiltre[i].integrator = 0;
        omronFiltre[i].kararli_durum = GPIO_PIN_SET;
        omronFiltre[i].kilitli = 0;
        omronFiltre[i].goruldu = 0;
    }

    omronSaglikli = 1;
    omronBeklemede = 0;
    omronDogrulandi = 0;
    omronReddedilen = 0;

    omronBeklemeBaslangic_ms = 0;
    omronSonDogrulama_ms = 0;

    omronReferansVar = 0;
    omronSonReflektorNo = 0;

    omronKonum = 0.0f;
    omronHiz = 0.0f;
    omronOrtalamaHiz = 0.0f;
    omronIvme = 0.0f;
    omronOncekiHiz = 0.0f;
    omronToplamYol = 0.0f;

    omronGecisDenendiIleri = 0U;
    omronGecisDenendiGeri = 0U;
    omronGecisHedefAktif = 0U;
    omronGecisHedefReflektor = 0U;
    omronGecisHedefYonu = 0;
    omronGecisHedefKonum = 0.0f;

    hallKonum = 0.0f;
    hallHiz = 0.0f;
    hallOrtalamaHiz = 0.0f;
    hallIvme = 0.0f;
    hallOncekiHiz = 0.0f;

    frenEncoderPalsGoruldu = 0U;
    frenEncoderPeriyotArtisi = 0U;
    frenEncoderHizDususu = 0U;
    frenEncoderSaglam = 0U;
    frenEncoderDurusDogrulandi = 0U;
    frenEncoderIzlemeAktif = 0U;
    frenEncoderPeriyotArtisSayisi = 0U;
    frenEncoderHizDususSayisi = 0U;
    frenEncoderBaslangicPals = 0U;
    frenEncoderOncekiPeriyot_us = 0U;
    frenEncoderOncekiHiz = 0.0f;

    H = 0U;
    hareketVeriKontrolAktif = 0U;
    hareketSonVeri_ms = simdi;
    hareketOncekiOmronOlay = 0U;
    hareketOncekiEncoderPals = 0U;

    yedek_mod = 0;

    hareketBaslangic_ms = simdi;
    HareketSuresi_ms = 0;

    tekerlek_durdu = 1;
    timerBasladi = 1;
}

static void SistemiSifirla(void)
{
    MotorlariDurdur();
    FrenleriAyarla(1, 1);

    timerBasladi = 0;
    oto_durum = OTO_BOSTA;

    OlcumuBaslat();

    timerBasladi = 0;
}

/* ========================================================= */
/*        FREN SONRASI ENCODER SAGLIK / DURUS KONTROLU       */
/* ========================================================= */

static void FrenEncoderIzlemeyiBaslat(void)
{
    frenEncoderPalsGoruldu = 0U;
    frenEncoderPeriyotArtisi = 0U;
    frenEncoderHizDususu = 0U;
    frenEncoderSaglam = 0U;
    frenEncoderDurusDogrulandi = 0U;

    frenEncoderPeriyotArtisSayisi = 0U;
    frenEncoderHizDususSayisi = 0U;
    frenEncoderBaslangicPals = encoderKabulEdilenPals;
    frenEncoderOncekiPeriyot_us = encoderSonPalsPeriyot_us;
    frenEncoderOncekiHiz = fabsf(hallHiz);
    frenEncoderIzlemeAktif = 1U;
}

static void FrenEncoderDurusunuKontrolEt(void)
{
    if (!frenEncoderIzlemeAktif)
    {
        return;
    }

    uint32_t simdi_ms = HAL_GetTick();
    uint32_t mevcutPals = encoderKabulEdilenPals;
    uint32_t mevcutPeriyot_us = encoderSonPalsPeriyot_us;
    float mevcutHiz = fabsf(hallHiz);

    /* Fren basladiktan sonra gercek ve filtrelenmis encoder palsi gorulmeli. */
    if (mevcutPals > frenEncoderBaslangicPals)
    {
        frenEncoderPalsGoruldu = 1U;
    }

    /* Yavaslarken palslarin arasi belirgin bicimde acilmalidir (en az yuzde 5). */
    if (mevcutPeriyot_us != 0U &&
        mevcutPeriyot_us != frenEncoderOncekiPeriyot_us)
    {
        if (frenEncoderOncekiPeriyot_us > 0U &&
            mevcutPeriyot_us >
                (frenEncoderOncekiPeriyot_us +
                 (frenEncoderOncekiPeriyot_us / 20U)))
        {
            if (frenEncoderPeriyotArtisSayisi < 255U)
            {
                frenEncoderPeriyotArtisSayisi++;
            }
        }

        frenEncoderOncekiPeriyot_us = mevcutPeriyot_us;
    }

    if (frenEncoderPeriyotArtisSayisi >= 2U)
    {
        frenEncoderPeriyotArtisi = 1U;
    }

    /* Filtrelenmis encoder hizi da fren boyunca azalmalidir. */
    if ((frenEncoderOncekiHiz - mevcutHiz) >= 0.05f)
    {
        if (frenEncoderHizDususSayisi < 255U)
        {
            frenEncoderHizDususSayisi++;
        }
    }

    frenEncoderOncekiHiz = mevcutHiz;

    if (frenEncoderHizDususSayisi >= 2U)
    {
        frenEncoderHizDususu = 1U;
    }

    /*
     * Encoder ancak fren sonrasinda pals urettigi ve yavaslamayi en az bir
     * bagimsiz bicimde (pals araligi veya hesaplanan hiz) gosterdigi zaman
     * saglam kabul edilir. Sabit HIGH/LOW veya donmus sayac bunu gecemez.
     */
    if (frenEncoderPalsGoruldu &&
        (frenEncoderPeriyotArtisi || frenEncoderHizDususu))
    {
        frenEncoderSaglam = 1U;
    }

    /*
     * Fren ancak saglamligi kanitlanan encoderin son palsinden sonra 2 saniye
     * gecmis, mevcut kod araci durmuş bulmus ve filtreli hiz sifira yaklasmis
     * ise birakilabilir.
     */
    if (frenEncoderSaglam &&
        tekerlek_durdu &&
        encoderSonGecerliPals_ms != 0U &&
        (simdi_ms - encoderSonGecerliPals_ms) >= DURMA_ZAMAN_ASIMI_MS &&
        mevcutHiz <= 0.10f)
    {
        frenEncoderDurusDogrulandi = 1U;
        frenEncoderIzlemeAktif = 0U;
    }
}

/* ========================================================= */
/*          HAREKETTE OMRON + ENCODER VERI KONTROLU          */
/* ========================================================= */

static void HareketVerisiniKontrolEt(uint32_t simdi_ms)
{
    uint32_t mevcutOmronOlay = omronOlayNo;
    uint32_t mevcutEncoderPals = encoderKabulEdilenPals;

    if (!hareketKomutuAktif)
    {
        H = 0U;
        hareketVeriKontrolAktif = 0U;
        hareketSonVeri_ms = simdi_ms;
        hareketOncekiOmronOlay = mevcutOmronOlay;
        hareketOncekiEncoderPals = mevcutEncoderPals;
        return;
    }

    /* Yeni ileri/geri komutunda 5 saniyelik kontrol penceresini bastan baslat. */
    if (!hareketVeriKontrolAktif)
    {
        H = 0U;
        hareketVeriKontrolAktif = 1U;
        hareketSonVeri_ms = simdi_ms;
        hareketOncekiOmronOlay = mevcutOmronOlay;
        hareketOncekiEncoderPals = mevcutEncoderPals;
        return;
    }

    /* Omron veya encoder kaynaklarindan herhangi biri yeni veri verdiyse akış vardir. */
    if (mevcutOmronOlay != hareketOncekiOmronOlay ||
        mevcutEncoderPals != hareketOncekiEncoderPals)
    {
        H = 0U;
        hareketSonVeri_ms = simdi_ms;
        hareketOncekiOmronOlay = mevcutOmronOlay;
        hareketOncekiEncoderPals = mevcutEncoderPals;
        return;
    }

    /* Iki kaynak da 5 saniye boyunca degismediyse hareket verisi hatasi ver. */
    if ((simdi_ms - hareketSonVeri_ms) >= HAREKET_VERI_ZAMAN_ASIMI_MS)
    {
        H = 1U;
    }
}

/* ========================================================= */
/*                     CONTROL TASK                          */
/* ========================================================= */

void StartControlTask(void *argument)
{
    uint8_t onceki_otonom = 0;
    uint8_t onceki_ileri = 0;
    uint8_t otonom_aktif = 0;
    uint8_t otonom_manuel_kilit = 0;

    HAL_GPIO_WritePin(
        canlilik_sinyali_GPIO_Port,
        canlilik_sinyali_Pin,
        GPIO_PIN_SET);

    MotorlariDurdur();
    FrenleriAyarla(0, 0);

    for (;;)
    {
        uint8_t ileri =
            (HAL_GPIO_ReadPin(
                Ileri_GPIO_Port,
                Ileri_Pin) == GPIO_PIN_SET);

        uint8_t geri =
            (HAL_GPIO_ReadPin(
                Geri_GPIO_Port,
                Geri_Pin) == GPIO_PIN_SET);

        uint8_t fren1 =
            (HAL_GPIO_ReadPin(
                fren_giris1_GPIO_Port,
                fren_giris1_Pin) == GPIO_PIN_SET);

        uint8_t fren2 =
            (HAL_GPIO_ReadPin(
                fren_giris2_GPIO_Port,
                fren_giris2_Pin) == GPIO_PIN_SET);

        uint8_t otonom_istek =
            (HAL_GPIO_ReadPin(
                otonom_GPIO_Port,
                otonom_Pin) == GPIO_PIN_SET);

        uint8_t manuel_mudahale =
            (ileri || geri || fren1 || fren2) ? 1U : 0U;

        /*
         * Otonom girisi LOW oldugunda onceki otonom istegi ve
         * manuel devralma kilidi temizlenir. Yeni bir otonom hareket
         * ancak giris yeniden LOW -> HIGH yapildiginda baslar.
         */
        if (!otonom_istek)
        {
            otonom_aktif = 0U;
            otonom_manuel_kilit = 0U;
        }

        if (!onceki_otonom && otonom_istek)
        {
            OlcumuBaslat();
            oto_durum = OTO_ILERI;
            otonom_aktif = 1U;
            otonom_manuel_kilit = 0U;
        }

        /*
         * Otonom hareket sirasinda ileri, geri veya fren gelirse
         * Raspberry Pi manuel kontrolu devralir.
         */
        if (otonom_aktif && manuel_mudahale)
        {
            otonom_aktif = 0U;
            otonom_manuel_kilit = 1U;
            oto_durum = OTO_BOSTA;
        }

        /* Manuel ileri komutu otonomdan bagimsiz olcumu baslatir. */
        if (!timerBasladi &&
            !otonom_aktif &&
            !onceki_ileri &&
            ileri)
        {
            OlcumuBaslat();
        }

        if (HAL_GPIO_ReadPin(
                Yazilim_Reset_GPIO_Port,
                Yazilim_Reset_Pin) == GPIO_PIN_SET)
        {
            SistemiSifirla();
        }
        else if (fren1 || fren2)
        {
            MotorlariDurdur();
            FrenleriAyarla(fren1, fren2);
            oto_durum = OTO_BOSTA;
        }
        else if (otonom_aktif &&
                 otonom_istek &&
                 !otonom_manuel_kilit)
        {
            switch ((OtonomDurum_t)oto_durum)
            {
                case OTO_ILERI:
                    MotorIleri();

                    if (LX >= OTONOM_ILERI_FREN_M)
                    {
                        MotorlariDurdur();
                        FrenleriAyarla(1, 1);
                        FrenEncoderIzlemeyiBaslat();
                        oto_durum = OTO_ILERI_FREN;
                    }
                    break;

                case OTO_ILERI_FREN:
                    MotorlariDurdur();
                    FrenleriAyarla(1, 1);

                    FrenEncoderDurusunuKontrolEt();

                    if (frenEncoderDurusDogrulandi)
                    {
                        FrenleriAyarla(0, 0);
                        oto_durum = OTO_GERI;
                    }
                    break;

                case OTO_GERI:
                    if (tekerlek_durdu ||
                        hareketYonu < 0)
                    {
                        MotorGeri();
                    }

                    if (LX <= OTONOM_GERI_FREN_M)
                    {
                        MotorlariDurdur();
                        FrenleriAyarla(1, 1);
                        FrenEncoderIzlemeyiBaslat();
                        oto_durum = OTO_GERI_FREN;
                    }
                    break;

                case OTO_GERI_FREN:
                    MotorlariDurdur();
                    FrenleriAyarla(1, 1);

                    FrenEncoderDurusunuKontrolEt();

                    if (frenEncoderDurusDogrulandi)
                    {
                        FrenleriAyarla(0, 0);
                        oto_durum = OTO_TAMAMLANDI;
                    }
                    break;

                case OTO_TAMAMLANDI:
                default:
                    MotorlariDurdur();
                    FrenleriAyarla(0, 0);
                    break;
            }
        }
        else
        {
            oto_durum = OTO_BOSTA;

            if (ileri &&
                !geri &&
                !fren1 &&
                !fren2 &&
                (tekerlek_durdu ||
                 hareketYonu > 0))
            {
                MotorIleri();
            }
            else if (geri &&
                     !ileri &&
                     !fren1 &&
                     !fren2 &&
                     (tekerlek_durdu ||
                      hareketYonu < 0))
            {
                MotorGeri();
            }
            else
            {
                MotorlariDurdur();
                FrenleriAyarla(fren1, fren2);
            }
        }

        onceki_otonom = otonom_istek;
        onceki_ileri = ileri;

        debug_oto_durum = oto_durum;

        vTaskDelay(pdMS_TO_TICKS(10));
    }
}

/* ========================================================= */
/*                REFLEKTÃƒâ€“R MESAFE HARÃ„Â°TASI                  */
/* ========================================================= */

static float MesafeHesapla(uint32_t R)
{
    if (R > 73U)
    {
        R = 73U;
    }

    float metre = 0.0f;

    for (uint32_t i = 1; i <= R; i++)
    {
        if (i == 1U)
        {
            metre += 6.0f;
        }
        else if (i <= 20U)
        {
            metre += 4.0f;
        }
        else if (i <= 39U)
        {
            metre += 0.1f;
        }
        else if (i == 40U)
        {
            metre += 2.1f;
        }
        else if (i <= 52U)
        {
            metre += 4.0f;
        }
        else if (i <= 61U)
        {
            metre += 0.1f;
        }
        else if (i == 62U)
        {
            metre += 3.1f;
        }
        else if (i <= 73U)
        {
            metre += 4.0f;
        }
    }

    return metre;
}

/* ========================================================= */
/*                    OMRON OKUMA                            */
/* ========================================================= */

static void OmronSayaciniGuncelle(uint8_t indeks)
{
    // Indeks parametresini yok sayıp hepsini aynı anda güncelliyoruz
    if (hareketYonu > 0)
    {
        if (RC1 < 73U) RC1++;
        if (RC2 < 73U) RC2++;
        if (RC3 < 73U) RC3++;
    }
    else
    {
        if (RC1 > 0U) RC1--;
        if (RC2 > 0U) RC2--;
        if (RC3 > 0U) RC3--;
    }

    // Üçünü de görüldü olarak işaretle
    omronFiltre[0].goruldu = 1;
    omronFiltre[1].goruldu = 1;
    omronFiltre[2].goruldu = 1;

    omronOlayNo++;
}

static void OmronFiltrele(
    uint8_t indeks,
    GPIO_PinState ham)
{
    OmronFiltre_t *filtre =
        &omronFiltre[indeks];

    if (ham == GPIO_PIN_RESET)
    {
        if (filtre->integrator <
            OMRON_FILTER_SEVIYESI)
        {
            filtre->integrator++;
        }

        if (filtre->integrator >=
                OMRON_FILTER_SEVIYESI &&
            filtre->kararli_durum !=
                GPIO_PIN_RESET)
        {
            filtre->kararli_durum =
                GPIO_PIN_RESET;

            if (!filtre->kilitli)
            {
                filtre->kilitli = 1;
                OmronSayaciniGuncelle(indeks);
            }
        }
    }
    else
    {
        if (filtre->integrator > 0U)
        {
            filtre->integrator--;
        }

        if (filtre->integrator == 0U)
        {
            filtre->kararli_durum =
                GPIO_PIN_SET;

            filtre->kilitli = 0;
        }
    }
}

static void OmronlariTara(void)
{
    if (!timerBasladi)
    {
        return;
    }

    OmronFiltrele(
        0,
        HAL_GPIO_ReadPin(
            Sensor1_GPIO_Port,
            Sensor1_Pin));

    OmronFiltrele(
        1,
        HAL_GPIO_ReadPin(
            Sensor2_GPIO_Port,
            Sensor2_Pin));

    OmronFiltrele(
        2,
        HAL_GPIO_ReadPin(
            Sensor3_GPIO_Port,
            Sensor3_Pin));
}

static bool OmronCiftDogrulama(
    uint32_t *reflektorNo)
{
    uint32_t r1 = RC1;
    uint32_t r2 = RC2;
    uint32_t r3 = RC3;

    if (omronFiltre[0].goruldu &&
        omronFiltre[1].goruldu &&
        r1 == r2)
    {
        *reflektorNo = r1;
        return true;
    }

    if (omronFiltre[0].goruldu &&
        omronFiltre[2].goruldu &&
        r1 == r3)
    {
        *reflektorNo = r1;
        return true;
    }

    if (omronFiltre[1].goruldu &&
        omronFiltre[2].goruldu &&
        r2 == r3)
    {
        *reflektorNo = r2;
        return true;
    }

    return false;
}

static bool OmronAdayiYeniMi(uint32_t aday)
{
    if (!omronReferansVar)
    {
        return true;
    }

    if (hareketYonu > 0)
    {
        return (aday > omronSonReflektorNo);
    }

    return (aday < omronSonReflektorNo);
}

static bool OmronlarSonReferanstaTamamlandi(void)
{
    if (!omronReferansVar)
    {
        return false;
    }

    uint8_t gorulenSensor = 0;
    uint8_t referanstaSensor = 0;

    if (omronFiltre[0].goruldu)
    {
        gorulenSensor++;

        if (RC1 == omronSonReflektorNo)
        {
            referanstaSensor++;
        }
    }

    if (omronFiltre[1].goruldu)
    {
        gorulenSensor++;

        if (RC2 == omronSonReflektorNo)
        {
            referanstaSensor++;
        }
    }

    if (omronFiltre[2].goruldu)
    {
        gorulenSensor++;

        if (RC3 == omronSonReflektorNo)
        {
            referanstaSensor++;
        }
    }

    return (gorulenSensor >= 2U &&
            gorulenSensor == referanstaSensor);
}

/* ========================================================= */
/*              OMRON REFERANSINI KABUL ET                   */
/* ========================================================= */

static void OmronReferansiniKabulEt(
    uint32_t reflektorNo,
    uint32_t simdi_ms)
{
    float yeniKonum =
        MesafeHesapla(reflektorNo);

    if (omronReferansVar)
    {
        uint32_t dt_ms =
            simdi_ms -
            omronSonDogrulama_ms;

        float dx =
            yeniKonum -
            omronKonum;

        if (dt_ms > 0U &&
            fabsf(dx) > 0.001f)
        {
            float dt =
                (float)dt_ms /
                1000.0f;

            float yeniHiz =
                dx / dt;

            omronToplamYol +=
                fabsf(dx);

            omronHiz =
                (0.60f * omronHiz) +
                (0.40f * yeniHiz);

            omronIvme =
                (0.70f * omronIvme) +
                (0.30f *
                 ((omronHiz -
                   omronOncekiHiz) / dt));

            omronOncekiHiz =
                omronHiz;
        }
    }
    else
    {
        omronToplamYol =
            fabsf(yeniKonum);
    }

    omronKonum =
        yeniKonum;

    omronSonReflektorNo =
        reflektorNo;

    omronSonDogrulama_ms =
        simdi_ms;

    omronReferansVar = 1;
    omronSaglikli = 1;
    omronBeklemede = 0;
    omronDogrulandi = 1;

    yedek_mod = 0;
}

static void OmronGecisHedefiniKur(void)
{
    uint32_t hedef = 0U;

    if (hareketYonu > 0)
    {
        if (omronGecisDenendiIleri)
        {
            return;
        }

        for (uint32_t i = 1U; i <= 73U; i++)
        {
            if (MesafeHesapla(i) >
                (hallKonum + 0.001f))
            {
                hedef = i;
                break;
            }
        }
    }
    else
    {
        if (omronGecisDenendiGeri)
        {
            return;
        }

        for (int32_t i = 73; i >= 1; i--)
        {
            if (MesafeHesapla((uint32_t)i) <
                (hallKonum - 0.001f))
            {
                hedef = (uint32_t)i;
                break;
            }
        }
    }

    if (hedef == 0U)
    {
        return;
    }

    omronGecisHedefReflektor = hedef;
    omronGecisHedefKonum = MesafeHesapla(hedef);
    omronGecisHedefYonu = hareketYonu;
    omronGecisHedefAktif = 1U;
}

static void OmronYenidenGecisiDene(uint32_t simdi_ms)
{
    uint8_t hedefeGelindi;

    if (omronSaglikli)
    {
        return;
    }

    if (!omronGecisHedefAktif)
    {
        OmronGecisHedefiniKur();

        if (!omronGecisHedefAktif)
        {
            return;
        }
    }

    if (hareketYonu != omronGecisHedefYonu)
    {
        omronGecisHedefAktif = 0U;
        OmronGecisHedefiniKur();
        return;
    }

    if (hareketYonu > 0)
    {
        hedefeGelindi =
            (hallKonum >= omronGecisHedefKonum);
    }
    else
    {
        hedefeGelindi =
            (hallKonum <= omronGecisHedefKonum);
    }

    if (!hedefeGelindi)
    {
        return;
    }

    if (hareketYonu > 0)
    {
        omronGecisDenendiIleri = 1U;
    }
    else
    {
        omronGecisDenendiGeri = 1U;
    }

    omronGecisHedefAktif = 0U;

    taskENTER_CRITICAL();

    RC1 = omronGecisHedefReflektor;
    RC2 = omronGecisHedefReflektor;
    RC3 = omronGecisHedefReflektor;

    taskEXIT_CRITICAL();

    OmronReferansiniKabulEt(
        omronGecisHedefReflektor,
        simdi_ms);
}

static void OmronDurumunuDegerlendir(
    uint32_t simdi_ms,
    uint32_t *oncekiOmronOlay)
{
    uint32_t mevcutOlay =
        omronOlayNo;

    if (!omronSaglikli)
    {
        *oncekiOmronOlay = mevcutOlay;
        omronBeklemede = 0U;
        return;
    }

    if (mevcutOlay != *oncekiOmronOlay)
    {
        *oncekiOmronOlay =
            mevcutOlay;

        if (!omronBeklemede)
        {
            omronBeklemede = 1;
            omronBeklemeBaslangic_ms =
                simdi_ms;
        }

        uint32_t adayReflektor = 0;

        if (OmronCiftDogrulama(
                &adayReflektor))
        {
            if (OmronAdayiYeniMi(
                    adayReflektor))
            {
                OmronReferansiniKabulEt(
                    adayReflektor,
                    simdi_ms);

                return;
            }

            if (OmronlarSonReferanstaTamamlandi())
            {
                omronSaglikli = 1;
                omronDogrulandi = 1;
                omronBeklemede = 0;
                yedek_mod = 0;

                return;
            }
        }
    }

    if (omronBeklemede &&
        (simdi_ms -
         omronBeklemeBaslangic_ms) >=
            OMRON_ESLESME_BEKLEME_MS)
    {
        uint32_t adayReflektor = 0;

        if (OmronCiftDogrulama(
                &adayReflektor))
        {
            if (OmronAdayiYeniMi(
                    adayReflektor))
            {
                OmronReferansiniKabulEt(
                    adayReflektor,
                    simdi_ms);

                return;
            }

            if (OmronlarSonReferanstaTamamlandi())
            {
                omronSaglikli = 1;
                omronDogrulandi = 1;
                omronBeklemede = 0;
                yedek_mod = 0;

                return;
            }
        }

        omronSaglikli = 0;
        omronDogrulandi = 0;
        omronBeklemede = 0;
        omronReddedilen++;

        yedek_mod = 1;
        OmronGecisHedefiniKur();
    }
}

/* ========================================================= */
/*                    NAVIGATION TASK                        */
/* ========================================================= */

void StartNavigationTask(void *argument)
{
    uint32_t oncekiKinematik_us =
        microsSTM();

    uint32_t oncekiOmronOlay = 0;

    for (;;)
    {
        uint32_t simdi_us =
            microsSTM();

        uint32_t simdi_ms =
            HAL_GetTick();

        OmronlariTara();

        HareketVerisiniKontrolEt(simdi_ms);

        if (!timerBasladi)
        {
            LX = 0.0f;
            SX = 0.0f;
            AS = 0.0f;
            AX = 0.0f;

            vTaskDelay(pdMS_TO_TICKS(1));
            continue;
        }

        HareketSuresi_ms =
            simdi_ms -
            hareketBaslangic_ms;

        if (encoderKabulEdilenPals == 0U ||
            encoderSonGecerliPals_ms == 0U)
        {
            tekerlek_durdu = 1;
        }
        else if ((simdi_ms -
                  encoderSonGecerliPals_ms) >=
                    DURMA_ZAMAN_ASIMI_MS)
        {
            tekerlek_durdu = 1;
        }
        else
        {
            tekerlek_durdu = 0;
        }

        hallKonum =
            (float)TekerlekTur *
            TEKER_CEVRESI_M;

        if (hallKonum < 0.0f)
        {
            hallKonum = 0.0f;
        }

        if (hallKonum > 186.0f)
        {
            hallKonum = 186.0f;
        }

        if ((uint32_t)(
                simdi_us -
                oncekiKinematik_us) >=
            20000U)
        {
            float dt =
                (float)(
                    simdi_us -
                    oncekiKinematik_us) /
                1000000.0f;

            float hallOlculenHiz =
                0.0f;

            if (!tekerlek_durdu &&
                hallPeriyot_us > 0U)
            {
                hallOlculenHiz =
                    ((float)hareketYonu *
                     TEKER_CEVRESI_M *
                     1000000.0f) /
                    (float)hallPeriyot_us;
            }

            hallHiz =
                (0.65f * hallHiz) +
                (0.35f *
                 hallOlculenHiz);

            if (tekerlek_durdu &&
                fabsf(hallHiz) < 0.02f)
            {
                hallHiz = 0.0f;
            }

            hallIvme =
                (0.70f * hallIvme) +
                (0.30f *
                 ((hallHiz -
                   hallOncekiHiz) / dt));

            if (tekerlek_durdu &&
                hallHiz == 0.0f &&
                fabsf(hallIvme) < 0.05f)
            {
                hallIvme = 0.0f;
            }

            hallOncekiHiz =
                hallHiz;

            oncekiKinematik_us =
                simdi_us;
        }

        if (HareketSuresi_ms > 0U)
        {
            float sure_s =
                (float)HareketSuresi_ms /
                1000.0f;

            hallOrtalamaHiz =
                ((float)hallToplamPals *
                 TEKER_CEVRESI_M) /
                sure_s;

            omronOrtalamaHiz =
                omronToplamYol /
                sure_s;
        }

        OmronDurumunuDegerlendir(
            simdi_ms,
            &oncekiOmronOlay);

        OmronYenidenGecisiDene(simdi_ms);

        if (omronReferansVar &&
            omronSonDogrulama_ms != 0U &&
            (simdi_ms -
             omronSonDogrulama_ms) >=
                OMRON_HIZ_ZAMAN_ASIMI_MS)
        {
            omronHiz = 0.0f;
            omronIvme = 0.0f;
            omronOncekiHiz = 0.0f;
        }

        if (!yedek_mod)
        {
            LX = omronKonum;
            SX = omronHiz;
            AS = omronOrtalamaHiz;
            AX = omronIvme;
        }
        else
        {
            LX = hallKonum;
            SX = hallHiz;
            AS = hallOrtalamaHiz;
            AX = hallIvme;
        }

        if (LX < 0.0f)
        {
            LX = 0.0f;
        }

        if (LX > 186.0f)
        {
            LX = 186.0f;
        }

        vTaskDelay(pdMS_TO_TICKS(1));
    }
}

void StartIMUTask(void *argument)
{
    (void)argument;

    for (;;)
    {
        vTaskDelay(pdMS_TO_TICKS(1000));
    }
}

/*                    DS18B20 OKUMA                          */
/* ========================================================= */

float DS18B20_ReadTemp(
    const uint8_t *rom_id)
{
    uint8_t data[9];
    float temp = -100.0f;

    if (OneWire_Reset() != 0)
    {
        return temp;
    }

    OneWire_WriteByte(0x55);

    for (int i = 0; i < 8; i++)
    {
        OneWire_WriteByte(
            rom_id[i]);
    }

    OneWire_WriteByte(0x44);

    vTaskDelay(pdMS_TO_TICKS(750));

    if (OneWire_Reset() != 0)
    {
        return temp;
    }

    OneWire_WriteByte(0x55);

    for (int i = 0; i < 8; i++)
    {
        OneWire_WriteByte(
            rom_id[i]);
    }

    OneWire_WriteByte(0xBE);

    for (int i = 0; i < 9; i++)
    {
        data[i] =
            OneWire_ReadByte();
    }

    if (OneWire_CRC8(data, 8) ==
        data[8])
    {
        int16_t raw =
            (int16_t)(
                (data[1] << 8) |
                 data[0]);

        temp =
            (float)raw / 16.0f;
    }

    return temp;
}

volatile uint8_t Bulunan_IDler[3][8] =
{
    {0}
};

volatile uint8_t Bulunan_Sensor_Sayisi = 0;
volatile uint8_t sensor_cevap = 0;

/* ========================================================= */
/*                    SICAKLIK TASK                          */
/* ========================================================= */

void StartSensorTask(void *argument)
{
    OneWire_Init();

    sensor_cevap =
        OneWire_Reset();

    if (OneWire_First())
    {
        do
        {
            if (Bulunan_Sensor_Sayisi < 3)
            {
                OneWire_GetFullROM(
                    (uint8_t *)
                    Bulunan_IDler[
                        Bulunan_Sensor_Sayisi]);

                Bulunan_Sensor_Sayisi++;
            }
        }
        while (OneWire_Next());
    }

    for (;;)
    {
        MT1 =
            DS18B20_ReadTemp(
                sensor1_id);

        sicaklik1_ok =
            (MT1 >= -55.0f && MT1 <= 125.0f);

        MT2 =
            DS18B20_ReadTemp(
                sensor2_id);

        sicaklik2_ok =
            (MT2 >= -55.0f && MT2 <= 125.0f);

        MT3 =
            DS18B20_ReadTemp(
                sensor3_id);

        sicaklik3_ok =
            (MT3 >= -55.0f && MT3 <= 125.0f);

        vTaskDelay(pdMS_TO_TICKS(2000));
    }
}

/* ========================================================= */
/*                     TELEMETRY TASK                        */
/* ========================================================= */

void StartTelemetryTask(void *argument)
{
    static char telemetryBuffer[512];
    uint32_t last_send_time = 0U;
    const uint32_t send_interval = 500U;

    for (;;)
    {
        uint32_t now = HAL_GetTick();

        if ((now - last_send_time) >= send_interval)
        {
            last_send_time = now;

            uint8_t frenAktif =
                (HAL_GPIO_ReadPin(
                     fren_cikis1_GPIO_Port,
                     fren_cikis1_Pin) == GPIO_PIN_RESET) ||
                (HAL_GPIO_ReadPin(
                     fren_cikis2_GPIO_Port,
                     fren_cikis2_Pin) == GPIO_PIN_RESET);

            uint8_t ileriAktif =
                (HAL_GPIO_ReadPin(
                     motor_ileri_GPIO_Port,
                     motor_ileri_Pin) == GPIO_PIN_RESET) &&
                (HAL_GPIO_ReadPin(
                     motor_geri_GPIO_Port,
                     motor_geri_Pin) == GPIO_PIN_SET);

            uint8_t geriAktif =
                (HAL_GPIO_ReadPin(
                     motor_geri_GPIO_Port,
                     motor_geri_Pin) == GPIO_PIN_RESET) &&
                (HAL_GPIO_ReadPin(
                     motor_ileri_GPIO_Port,
                     motor_ileri_Pin) == GPIO_PIN_SET);

            uint8_t telemetriIleri = 0U;
            uint8_t telemetriGeri = 0U;
            uint8_t telemetriFren = 0U;
            uint8_t telemetriBosta = 0U;

            if (frenAktif)
            {
                telemetriFren = 1U;
            }
            else if (ileriAktif)
            {
                telemetriIleri = 1U;
            }
            else if (geriAktif)
            {
                telemetriGeri = 1U;
            }
            else
            {
                telemetriBosta = 1U;
            }

            int len = snprintf(
                telemetryBuffer,
                sizeof(telemetryBuffer),
                "LX:%.3f,"
                "AX:%.3f,"
                "SX:%.3f,"
                "AS:%.3f,"
                "MT1:%.2f,MT2:%.2f,MT3:%.2f,"
                "RC1:%lu,RC2:%lu,RC3:%lu,"
                "F:%u,B:%u,BR:%u,E:%u,H:%u\n",
                LX,
                AX,
                SX,
                AS,
                MT1,
                MT2,
                MT3,
                (unsigned long)RC1,
                (unsigned long)RC2,
                (unsigned long)RC3,
                (unsigned int)telemetriIleri,
                (unsigned int)telemetriGeri,
                (unsigned int)telemetriFren,
                (unsigned int)telemetriBosta,
                (unsigned int)H);

            if (len > 0 && len < (int)sizeof(telemetryBuffer))
            {
                if (CDC_Transmit_FS(
                        (uint8_t *)telemetryBuffer,
                        (uint16_t)len) == USBD_OK)
                {
                    HAL_GPIO_WritePin(
                        LD4_GPIO_Port,
                        LD4_Pin,
                        GPIO_PIN_RESET);
                }
                else
                {
                    HAL_GPIO_WritePin(
                        LD4_GPIO_Port,
                        LD4_Pin,
                        GPIO_PIN_SET);
                }
            }
        }

        vTaskDelay(pdMS_TO_TICKS(10));
    }
}

/* ========================================================= */
/*                ENKODER EXTI KESMESİ                       */
/* ========================================================= */

void HAL_GPIO_EXTI_Callback(
    uint16_t GPIO_Pin)
{
    uint32_t su_an_ms = HAL_GetTick();
    uint32_t simdi_us;
    uint32_t lowSuresi_us;
    uint32_t oncekiYukselen_us;
    uint32_t periyot_us;
    uint32_t highSuresi_us;
    uint32_t dutyYuzde;
    uint32_t turSuresi_us;
    uint16_t eklenecekPals;
    GPIO_PinState pinDurumu;

    if (su_an_ms < 500U ||
        !timerBasladi ||
        GPIO_Pin != hallSensor_Pin)
    {
        return;
    }

    simdi_us = microsSTM();

    pinDurumu = HAL_GPIO_ReadPin(
        hallSensor_GPIO_Port,
        hallSensor_Pin);

    if (pinDurumu == GPIO_PIN_RESET)
    {

        if (encoderLowBasladi)
        {
            encoderReddedilenPals++;
            return;
        }

        encoderDusenKenar_us = simdi_us;
        encoderLowBasladi = 1U;
        return;
    }

    if (!encoderLowBasladi)
    {
        encoderReddedilenPals++;
        return;
    }

    lowSuresi_us =
        simdi_us - encoderDusenKenar_us;

    encoderLowBasladi = 0U;

    if (lowSuresi_us < ENCODER_MIN_LOW_US)
    {
        encoderReddedilenPals++;
        encoderSonYukselen_us = simdi_us;
        encoderIlkPalsAday = 0U;
        return;
    }

    if (encoderSonYukselen_us == 0U)
    {
        encoderSonYukselen_us = simdi_us;
        encoderIlkPalsAday = 1U;
        return;
    }

    oncekiYukselen_us = encoderSonYukselen_us;
    periyot_us = simdi_us - oncekiYukselen_us;
    highSuresi_us = encoderDusenKenar_us - oncekiYukselen_us;

    encoderSonYukselen_us = simdi_us;

    if (periyot_us < ENCODER_MIN_PERIYOT_US ||
        highSuresi_us < ENCODER_MIN_HIGH_US ||
        lowSuresi_us >= periyot_us)
    {
        encoderReddedilenPals++;
        encoderIlkPalsAday = 0U;
        return;
    }

    dutyYuzde =
        (lowSuresi_us * 100U) /
        periyot_us;

    if (dutyYuzde < ENCODER_DUTY_MIN_YUZDE ||
        dutyYuzde > ENCODER_DUTY_MAX_YUZDE)
    {
        encoderReddedilenPals++;
        encoderIlkPalsAday = 0U;
        return;
    }

    eklenecekPals =
        encoderIlkPalsAday ? 2U : 1U;

    encoderIlkPalsAday = 0U;
    encoderFiltreKilitli = 1U;

    if (encoderPalsSayaci == 0U)
    {
        encoderTurBaslangic_us =
            (eklenecekPals == 2U) ?
            oncekiYukselen_us : simdi_us;
    }

    encoderPalsSayaci += eklenecekPals;
    encoderKabulEdilenPals += eklenecekPals;
    encoderSonPalsPeriyot_us = periyot_us;

    encoderSonGecerliPals_ms = su_an_ms;
    hallKullanilabilir = 1U;
    tekerlek_durdu = 0U;

    if (encoderPalsSayaci < ENCODER_PPR)
    {
        return;
    }

    encoderPalsSayaci -= ENCODER_PPR;

    turSuresi_us =
        simdi_us - encoderTurBaslangic_us;

    if (turSuresi_us < ENCODER_MIN_TUR_SURESI_US)
    {
        if (encoderKabulEdilenPals >= ENCODER_PPR)
        {
            encoderKabulEdilenPals -= ENCODER_PPR;
        }

        encoderReddedilenPals += ENCODER_PPR;
        encoderFiltreKilitli = 0U;
        encoderTurBaslangic_us =
            (encoderPalsSayaci > 0U) ? simdi_us : 0U;
        return;
    }

    encoderTurBaslangic_us =
        (encoderPalsSayaci > 0U) ? simdi_us : 0U;

    if (encoderSonTamTur_us != 0U)
    {
        hallPeriyot_us =
            simdi_us - encoderSonTamTur_us;
    }

    encoderSonTamTur_us = simdi_us;
    hallSonPals_us = simdi_us;
    hallSonPals_ms = su_an_ms;
    hallToplamPals++;
    hallKullanilabilir = 1U;
    tekerlek_durdu = 0U;

    if (hareketYonu > 0)
    {
        TekerlekTur++;
    }
    else
    {
        TekerlekTur--;
    }
}

/* ========================================================= */
/*                 STACK OVERFLOW HOOK                       */
/* ========================================================= */

void vApplicationStackOverflowHook(
    TaskHandle_t xTask,
    char *pcTaskName)
{
    (void)xTask;
    (void)pcTaskName;

    while (1)
    {
    }
}

/* USER CODE END Application */
